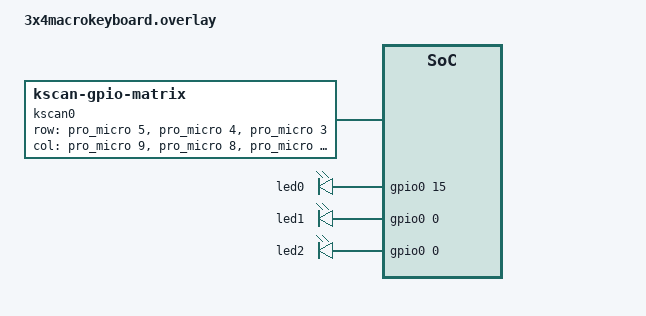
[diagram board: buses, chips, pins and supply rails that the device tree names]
/*
 * Copyright (c) 2020 The ZMK Contributors
 *
 * SPDX-License-Identifier: MIT
 */

#include <dt-bindings/zmk/matrix_transform.h>
#include <dt-bindings/zmk/outputs.h>
#include <dt-bindings/zmk/bt.h>

/ {
    chosen {
        zmk,kscan = &kscan0;
    };

    kscan0: kscan {
        compatible = "zmk,kscan-gpio-matrix";
        wakeup-source;

        diode-direction = "col2row";

         row-gpios
            = <&pro_micro 5 (GPIO_ACTIVE_HIGH | GPIO_PULL_DOWN)>
            , <&pro_micro 4 (GPIO_ACTIVE_HIGH | GPIO_PULL_DOWN)>
            , <&pro_micro 3 (GPIO_ACTIVE_HIGH | GPIO_PULL_DOWN)>
            ;

        col-gpios
            = <&pro_micro 9 GPIO_ACTIVE_HIGH>
            , <&pro_micro 8 GPIO_ACTIVE_HIGH>
            , <&pro_micro 7 GPIO_ACTIVE_HIGH>
            , <&pro_micro 6 GPIO_ACTIVE_HIGH>
            ;
    };
    aliases {
        led-red = &led0;
        led-green = &led1;
        led-blue = &led2;
    };

    leds {
        compatible = "gpio-leds";
        status = "okay";
        led0: led_0 {
            gpios = <&gpio0 15 GPIO_ACTIVE_HIGH>;  // red LED, connected to P0.26     
        };
        led1: led_1 {
            gpios = <&gpio0 0 GPIO_ACTIVE_HIGH>;  // green LED, connected to P0.30
        };
        led2: led_2 {
            gpios = <&gpio0 0 GPIO_ACTIVE_HIGH>;  // blue LED, connected to P0.06
        };
    };
};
